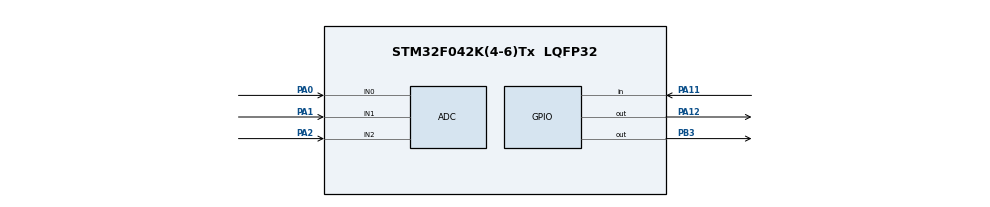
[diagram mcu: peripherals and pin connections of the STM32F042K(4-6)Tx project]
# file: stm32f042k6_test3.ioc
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ADC.ContinuousConvMode=DISABLE
ADC.DMAContinuousRequests=ENABLE
ADC.EOCSelection=ADC_EOC_SEQ_CONV
ADC.ExternalTrigConv=ADC_SOFTWARE_START
ADC.Overrun=ADC_OVR_DATA_PRESERVED
ADC.SamplingTime=ADC_SAMPLETIME_28CYCLES_5
Dma.ADC.0.Direction=DMA_PERIPH_TO_MEMORY
Dma.ADC.0.Instance=DMA1_Channel1
Dma.ADC.0.MemDataAlignment=DMA_MDATAALIGN_WORD
Dma.ADC.0.MemInc=DMA_MINC_ENABLE
Dma.ADC.0.Mode=DMA_CIRCULAR
Dma.ADC.0.PeriphDataAlignment=DMA_PDATAALIGN_WORD
Dma.ADC.0.PeriphInc=DMA_PINC_DISABLE
Dma.ADC.0.Priority=DMA_PRIORITY_LOW
Dma.Request0=ADC
Mcu.Family=STM32F0
Mcu.Name=STM32F042K(4-6)Tx
Mcu.Package=LQFP32
NVIC.ADC1_IRQn=true\:0\:0\:false\:false\:true\:true\:true
NVIC.DMA1_Channel1_IRQn=true\:0\:0\:false\:false\:true\:false\:true
PA0.Mode=IN0
PA0.Signal=ADC_IN0
PA1.Mode=IN1
PA1.Signal=ADC_IN1
PA11.Signal=GPIO_Input
PA12.Signal=GPIO_Output
PA2.Mode=IN2
PA2.Signal=ADC_IN2
PB3.Signal=GPIO_Output
ProjectManager.HeapSize=0x200
ProjectManager.StackSize=0x400
ProjectManager.TargetToolchain=STM32CubeIDE
board=custom

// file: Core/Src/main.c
/* USER CODE BEGIN Header */
/**
  ******************************************************************************
  * @file           : main.c
  * @brief          : Main program body
  ******************************************************************************
  * @attention
  *
  * <h2><center>&copy; Copyright (c) 2021 STMicroelectronics.
  * All rights reserved.</center></h2>
  *
  * This software component is licensed by ST under BSD 3-Clause license,
  * the "License"; You may not use this file except in compliance with the
  * License. You may obtain a copy of the License at:
  *                        opensource.org/licenses/BSD-3-Clause
  *
  ******************************************************************************
  */
/* USER CODE END Header */
#include "main.h"

ADC_HandleTypeDef hadc;
DMA_HandleTypeDef hdma_adc;

/* USER CODE BEGIN PV */
uint32_t buffer[3];
float data[3];
/* USER CODE END PV */

void SystemClock_Config(void);
static void MX_GPIO_Init(void);
static void MX_DMA_Init(void);
static void MX_ADC_Init(void);

/* USER CODE BEGIN 0 */
void HAL_ADC_ConvHalfCpltCallback(ADC_HandleTypeDef* hadc)
{
	__NOP();
}

void HAL_ADC_ConvCpltCallback(ADC_HandleTypeDef* hadc)
{
	for (int i =0; i<3; i++) {
	  data[i] = buffer[i] / 4096.0 * 3.3;
	}
}
/* USER CODE END 0 */

int main(void)
{

  /* MCU Configuration--------------------------------------------------------*/

  /* Reset of all peripherals, Initializes the Flash interface and the Systick. */
  HAL_Init();

  /* Configure the system clock */
  SystemClock_Config();

  /* Initialize all configured peripherals */
  MX_GPIO_Init();
  MX_DMA_Init();
  MX_ADC_Init();
  /* USER CODE BEGIN 2 */
  HAL_ADC_Start_DMA(&hadc, buffer, 3);
  HAL_ADC_Start_IT(&hadc);
  /* USER CODE END 2 */

  /* Infinite loop */
  /* USER CODE BEGIN WHILE */
  while (1)
  {
	  HAL_ADC_Start_IT(&hadc);

	  int fusepin = HAL_GPIO_ReadPin(GPIOB, GPIO_PIN_5);
	  HAL_GPIO_WritePin(GPIOB, GPIO_PIN_3, fusepin);
	  HAL_GPIO_WritePin(GPIOA, GPIO_PIN_12, fusepin);

	  HAL_ADC_Start(&hadc);
    /* USER CODE END WHILE */

  }
}

void SystemClock_Config(void)
{
  RCC_OscInitTypeDef RCC_OscInitStruct = {0};
  RCC_ClkInitTypeDef RCC_ClkInitStruct = {0};

  /** Initializes the RCC Oscillators according to the specified parameters
  * in the RCC_OscInitTypeDef structure.
  */
  RCC_OscInitStruct.OscillatorType = RCC_OSCILLATORTYPE_HSI|RCC_OSCILLATORTYPE_HSI14;
  RCC_OscInitStruct.HSIState = RCC_HSI_ON;
  RCC_OscInitStruct.HSI14State = RCC_HSI14_ON;
  RCC_OscInitStruct.HSICalibrationValue = RCC_HSICALIBRATION_DEFAULT;
  RCC_OscInitStruct.HSI14CalibrationValue = 16;
  RCC_OscInitStruct.PLL.PLLState = RCC_PLL_NONE;
  if (HAL_RCC_OscConfig(&RCC_OscInitStruct) != HAL_OK)
  {
    Error_Handler();
  }
  /** Initializes the CPU, AHB and APB buses clocks
  */
  RCC_ClkInitStruct.ClockType = RCC_CLOCKTYPE_HCLK|RCC_CLOCKTYPE_SYSCLK
                              |RCC_CLOCKTYPE_PCLK1;
  RCC_ClkInitStruct.SYSCLKSource = RCC_SYSCLKSOURCE_HSI;
  RCC_ClkInitStruct.AHBCLKDivider = RCC_SYSCLK_DIV1;
  RCC_ClkInitStruct.APB1CLKDivider = RCC_HCLK_DIV1;

  if (HAL_RCC_ClockConfig(&RCC_ClkInitStruct, FLASH_LATENCY_0) != HAL_OK)
  {
    Error_Handler();
  }
}

static void MX_ADC_Init(void)
{

  ADC_ChannelConfTypeDef sConfig = {0};

  /** Configure the global features of the ADC (Clock, Resolution, Data Alignment and number of conversion)
  */
  hadc.Instance = ADC1;
  hadc.Init.ClockPrescaler = ADC_CLOCK_ASYNC_DIV1;
  hadc.Init.Resolution = ADC_RESOLUTION_12B;
  hadc.Init.DataAlign = ADC_DATAALIGN_RIGHT;
  hadc.Init.ScanConvMode = ADC_SCAN_DIRECTION_FORWARD;
  hadc.Init.EOCSelection = ADC_EOC_SEQ_CONV;
  hadc.Init.LowPowerAutoWait = DISABLE;
  hadc.Init.LowPowerAutoPowerOff = DISABLE;
  hadc.Init.ContinuousConvMode = DISABLE;
  hadc.Init.DiscontinuousConvMode = DISABLE;
  hadc.Init.ExternalTrigConv = ADC_SOFTWARE_START;
  hadc.Init.ExternalTrigConvEdge = ADC_EXTERNALTRIGCONVEDGE_NONE;
  hadc.Init.DMAContinuousRequests = ENABLE;
  hadc.Init.Overrun = ADC_OVR_DATA_PRESERVED;
  if (HAL_ADC_Init(&hadc) != HAL_OK)
  {
    Error_Handler();
  }
  /** Configure for the selected ADC regular channel to be converted.
  */
  sConfig.Channel = ADC_CHANNEL_0;
  sConfig.Rank = ADC_RANK_CHANNEL_NUMBER;
  sConfig.SamplingTime = ADC_SAMPLETIME_28CYCLES_5;
  if (HAL_ADC_ConfigChannel(&hadc, &sConfig) != HAL_OK)
  {
    Error_Handler();
  }
  /** Configure for the selected ADC regular channel to be converted.
  */
  sConfig.Channel = ADC_CHANNEL_1;
  if (HAL_ADC_ConfigChannel(&hadc, &sConfig) != HAL_OK)
  {
    Error_Handler();
  }
  /** Configure for the selected ADC regular channel to be converted.
  */
  sConfig.Channel = ADC_CHANNEL_2;
  if (HAL_ADC_ConfigChannel(&hadc, &sConfig) != HAL_OK)
  {
    Error_Handler();
  }

}

static void MX_DMA_Init(void)
{

  /* DMA controller clock enable */
  __HAL_RCC_DMA1_CLK_ENABLE();

  /* DMA interrupt init */
  /* DMA1_Channel1_IRQn interrupt configuration */
  HAL_NVIC_SetPriority(DMA1_Channel1_IRQn, 0, 0);
  HAL_NVIC_EnableIRQ(DMA1_Channel1_IRQn);

}

static void MX_GPIO_Init(void)
{
  GPIO_InitTypeDef GPIO_InitStruct = {0};

  /* GPIO Ports Clock Enable */
  __HAL_RCC_GPIOA_CLK_ENABLE();
  __HAL_RCC_GPIOB_CLK_ENABLE();

  /*Configure GPIO pin Output Level */
  HAL_GPIO_WritePin(GPIOA, GPIO_PIN_12, GPIO_PIN_RESET);

  /*Configure GPIO pin Output Level */
  HAL_GPIO_WritePin(GPIOB, GPIO_PIN_3, GPIO_PIN_RESET);

  /*Configure GPIO pin : PA11 */
  GPIO_InitStruct.Pin = GPIO_PIN_11;
  GPIO_InitStruct.Mode = GPIO_MODE_INPUT;
  GPIO_InitStruct.Pull = GPIO_NOPULL;
  HAL_GPIO_Init(GPIOA, &GPIO_InitStruct);

  /*Configure GPIO pin : PA12 */
  GPIO_InitStruct.Pin = GPIO_PIN_12;
  GPIO_InitStruct.Mode = GPIO_MODE_OUTPUT_PP;
  GPIO_InitStruct.Pull = GPIO_NOPULL;
  GPIO_InitStruct.Speed = GPIO_SPEED_FREQ_LOW;
  HAL_GPIO_Init(GPIOA, &GPIO_InitStruct);

  /*Configure GPIO pin : PB3 */
  GPIO_InitStruct.Pin = GPIO_PIN_3;
  GPIO_InitStruct.Mode = GPIO_MODE_OUTPUT_PP;
  GPIO_InitStruct.Pull = GPIO_NOPULL;
  GPIO_InitStruct.Speed = GPIO_SPEED_FREQ_LOW;
  HAL_GPIO_Init(GPIOB, &GPIO_InitStruct);

}

void Error_Handler(void)
{
  __disable_irq();
  while (1)
  {
  }
}

/************************ (C) COPYRIGHT STMicroelectronics *****END OF FILE****/
